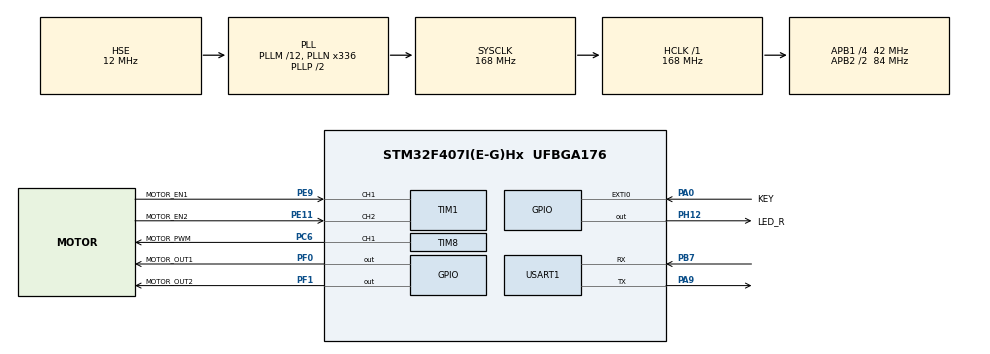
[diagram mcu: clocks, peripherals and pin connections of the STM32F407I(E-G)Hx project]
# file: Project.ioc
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Mcu.Family=STM32F4
Mcu.Name=STM32F407I(E-G)Hx
Mcu.Package=UFBGA176
NVIC.EXTI0_IRQn=true\:0\:0\:false\:false\:true\:true\:true\:true
NVIC.PriorityGroup=NVIC_PRIORITYGROUP_4
NVIC.TIM6_DAC_IRQn=true\:0\:0\:false\:false\:true\:true\:true\:true
NVIC.USART1_IRQn=true\:0\:0\:false\:false\:true\:true\:true\:true
PA0-WKUP.GPIO_Label=KEY
PA0-WKUP.GPIO_ModeDefaultEXTI=GPIO_MODE_IT_FALLING
PA0-WKUP.Signal=GPXTI0
PA9.Mode=Asynchronous
PA9.Signal=USART1_TX
PB7.Mode=Asynchronous
PB7.Signal=USART1_RX
PC6.GPIO_Label=MOTOR_PWM
PC6.Signal=S_TIM8_CH1
PE11.GPIO_Label=MOTOR_EN2
PE11.Signal=S_TIM1_CH2
PE9.GPIO_Label=MOTOR_EN1
PE9.Signal=S_TIM1_CH1
PF0.GPIO_Label=MOTOR_OUT1
PF0.Signal=GPIO_Output
PF1.GPIO_Label=MOTOR_OUT2
PF1.Signal=GPIO_Output
PH0-OSC_IN.Mode=HSE-External-Oscillator
PH0-OSC_IN.Signal=RCC_OSC_IN
PH1-OSC_OUT.Mode=HSE-External-Oscillator
PH1-OSC_OUT.Signal=RCC_OSC_OUT
PH12.GPIO_Label=LED_R
PH12.Signal=GPIO_Output
ProjectManager.HeapSize=0x200
ProjectManager.StackSize=0x400
ProjectManager.TargetToolchain=Makefile
RCC.48MHZClocksFreq_Value=48000000
RCC.AHBFreq_Value=168000000
RCC.APB1CLKDivider=RCC_HCLK_DIV4
RCC.APB1Freq_Value=42000000
RCC.APB1TimFreq_Value=84000000
RCC.APB2CLKDivider=RCC_HCLK_DIV2
RCC.APB2Freq_Value=84000000
RCC.APB2TimFreq_Value=168000000
RCC.CortexFreq_Value=168000000
RCC.HCLKFreq_Value=168000000
RCC.HSE_VALUE=12000000
RCC.HSI_VALUE=16000000
RCC.LSE_VALUE=32768
RCC.PLLM=12
RCC.PLLN=336
RCC.PLLQ=7
RCC.PLLSourceVirtual=RCC_PLLSOURCE_HSE
RCC.SYSCLKFreq_VALUE=168000000
RCC.SYSCLKSource=RCC_SYSCLKSOURCE_PLLCLK
RCC.VCOOutputFreq_Value=336000000
SH.S_TIM1_CH1.0=TIM1_CH1,Encoder_Interface
SH.S_TIM1_CH2.0=TIM1_CH2,Encoder_Interface
SH.S_TIM8_CH1.0=TIM8_CH1,PWM Generation1 CH1
TIM1.EncoderMode=TIM_ENCODERMODE_TI12
TIM6.Period=10000-1
TIM6.Prescaler=84-1
TIM8.Channel-PWM\ Generation1\ CH1=TIM_CHANNEL_1
TIM8.Period=5000-1
TIM8.Prescaler=34-1
USART1.VirtualMode=VM_ASYNC
VP_TIM6_VS_ClockSourceINT.Mode=Enable_Timer
board=custom

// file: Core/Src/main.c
/* USER CODE BEGIN Header */
/**
  ******************************************************************************
  * @file           : main.c
  * @brief          : Main program body
  ******************************************************************************
  * @attention
  *
  * Copyright (c) 2026 STMicroelectronics.
  * All rights reserved.
  *
  * This software is licensed under terms that can be found in the LICENSE file
  * in the root directory of this software component.
  * If no LICENSE file comes with this software, it is provided AS-IS.
  *
  ******************************************************************************
  */
/* USER CODE END Header */
#include "main.h"
#include "tim.h"
#include "usart.h"
#include "gpio.h"

/* USER CODE BEGIN Includes */
#include "app_task.h"
/* USER CODE END Includes */

void SystemClock_Config(void);

int main(void)
{

  /* MCU Configuration--------------------------------------------------------*/

  /* Reset of all peripherals, Initializes the Flash interface and the Systick. */
  HAL_Init();

  /* Configure the system clock */
  SystemClock_Config();

  /* Initialize all configured peripherals */
  MX_GPIO_Init();
  MX_TIM6_Init();
  MX_TIM1_Init();
  MX_TIM8_Init();
  MX_USART1_UART_Init();
  /* USER CODE BEGIN 2 */
  HAL_TIM_Base_Start_IT(&htim6);
  User_init();
  app_startMotor();
  /* USER CODE END 2 */

  /* Infinite loop */
  /* USER CODE BEGIN WHILE */
  while (1)
  {
    app_task();
    /* USER CODE END WHILE */

  }
}

void SystemClock_Config(void)
{
  RCC_OscInitTypeDef RCC_OscInitStruct = {0};
  RCC_ClkInitTypeDef RCC_ClkInitStruct = {0};

  /** Configure the main internal regulator output voltage
  */
  __HAL_RCC_PWR_CLK_ENABLE();
  __HAL_PWR_VOLTAGESCALING_CONFIG(PWR_REGULATOR_VOLTAGE_SCALE1);

  /** Initializes the RCC Oscillators according to the specified parameters
  * in the RCC_OscInitTypeDef structure.
  */
  RCC_OscInitStruct.OscillatorType = RCC_OSCILLATORTYPE_HSE;
  RCC_OscInitStruct.HSEState = RCC_HSE_ON;
  RCC_OscInitStruct.PLL.PLLState = RCC_PLL_ON;
  RCC_OscInitStruct.PLL.PLLSource = RCC_PLLSOURCE_HSE;
  RCC_OscInitStruct.PLL.PLLM = 12;
  RCC_OscInitStruct.PLL.PLLN = 336;
  RCC_OscInitStruct.PLL.PLLP = RCC_PLLP_DIV2;
  RCC_OscInitStruct.PLL.PLLQ = 7;
  if (HAL_RCC_OscConfig(&RCC_OscInitStruct) != HAL_OK)
  {
    Error_Handler();
  }

  /** Initializes the CPU, AHB and APB buses clocks
  */
  RCC_ClkInitStruct.ClockType = RCC_CLOCKTYPE_HCLK|RCC_CLOCKTYPE_SYSCLK
                              |RCC_CLOCKTYPE_PCLK1|RCC_CLOCKTYPE_PCLK2;
  RCC_ClkInitStruct.SYSCLKSource = RCC_SYSCLKSOURCE_PLLCLK;
  RCC_ClkInitStruct.AHBCLKDivider = RCC_SYSCLK_DIV1;
  RCC_ClkInitStruct.APB1CLKDivider = RCC_HCLK_DIV4;
  RCC_ClkInitStruct.APB2CLKDivider = RCC_HCLK_DIV2;

  if (HAL_RCC_ClockConfig(&RCC_ClkInitStruct, FLASH_LATENCY_5) != HAL_OK)
  {
    Error_Handler();
  }
}

void Error_Handler(void)
{
  __disable_irq();
  while (1)
  {
  }
}
